# GD32L23x register map
File version: 1.0
CPU: CM23 r0p0, little endian, MPU, FPU, 4 interrupt priority bits
Registers are 32-bit, read-write, reset 0x0 unless marked. A register's access mark holds for its fields unless they carry their own. Offsets are from the block's base; [hi:lo] are bit positions; {n}, {i} and the like mark numbered series.

## SLCD — Segment LCD controller
Base 0x40002400
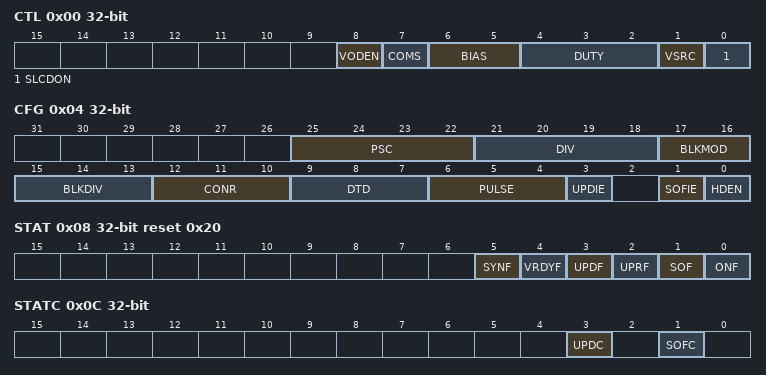
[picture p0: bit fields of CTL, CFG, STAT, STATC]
0x00 CTL — Control register
  [8] VODEN — Voltage output driver enable
  [7] COMS — Common/segment padselect
  [6:5] BIAS — Bias select
  [4:2] DUTY — Duty select
  [1] VSRC — SLCD voltage source
  [0] SLCDON — SLCD controller start
0x04 CFG — SLCD configuration register
  [25:22] PSC — SLCD clock prescaler
  [21:18] DIV — SLCD clock divider
  [17:16] BLKMOD — Blink mode
  [15:13] BLKDIV — Blink frequency divider
  [12:10] CONR — Contrast ratio
  [9:7] DTD — Dead time duration
  [6:4] PULSE — Pulse on duration
  [3] UPDIE — SLCD update done interrupt enable
  [1] SOFIE — Start of frame interrupt enable
  [0] HDEN — High drive enable
0x08 STAT access per field reset 0x20 — SLCD status flag register
  [5] SYNF ro — SLCD_CFG register synchronization flag
  [4] VRDYF ro — SLCD voltage ready flag
  [3] UPDF ro — Update SLCD data done flag
  [2] UPRF rw — Update SLCD data request flag
  [1] SOF ro — Start of frame flag
  [0] ONF ro — SLCD controller on flag
0x0C STATC — SLCD status flag clear register
  [3] UPDC — SLCD data update done clear bit
  [1] SOFC — Start of frame flag clear
{0x14+8i} DATA{i} (i=0..7) — SLCD display data register
  [31:0] SEG_DATA{i} — Each bit corresponds to one segment to display

## VREF
Base 0x40010030
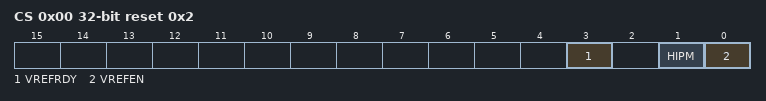
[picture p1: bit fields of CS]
0x00 CS access per field reset 0x2 — Control and status register
  [3] VREFRDY ro — VREF ready
  [1] HIPM rw — High impedance mode
  [0] VREFEN rw — VREF enable
0x04 CALIB — Calibration register
  [5:0] VREFCAL — VREF calibration

## USBD — Universal serial bus full-speed device interface
Base 0x40005C00
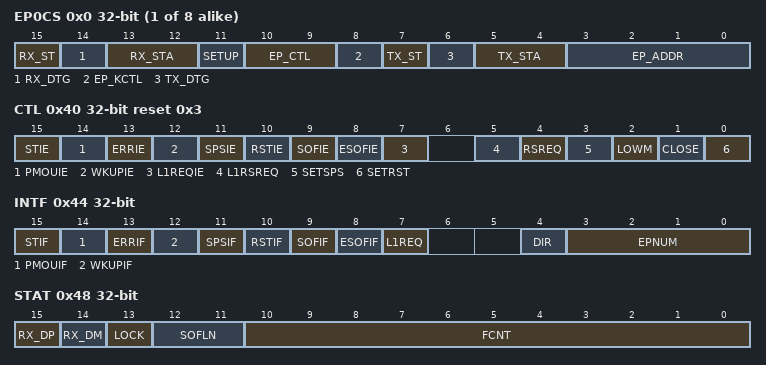
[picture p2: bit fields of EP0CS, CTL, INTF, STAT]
{0x0+4i} EP{i}CS access per field (i=0..7) — endpoint {i} register
  [15] RX_ST rw — Reception Successful Transferred
  [14] RX_DTG rw — Reception Data PID Toggle
  [13:12] RX_STA rw — Reception status bits
  [11] SETUP ro — Setup transaction completed
  [10:9] EP_CTL rw — Endpoint type control
  [8] EP_KCTL rw — Endpoint kind control
  [7] TX_ST rw — Transmission Successful Transfer
  [6] TX_DTG rw — Transmission Data PID Toggle
  [5:4] TX_STA rw — Status bits, for transmission transfers
  [3:0] EP_ADDR rw — Endpoint address
0x40 CTL reset 0x3 — control register
  [15] STIE — Successful transfer interrupt enable
  [14] PMOUIE — Packet memory overrun / underrun interrupt enable
  [13] ERRIE — Error interrupt mask
  [12] WKUPIE — Wakeup interrupt mask
  [11] SPSIE — Suspend state interrupt enable
  [10] RSTIE — USB reset interrupt enable
  [9] SOFIE — Start of frame interrupt enable
  [8] ESOFIE — Expected start of frame interrupt enable
  [7] L1REQIE — LPM L1 state request interrupt enable
  [5] L1RSREQ — LPM L1 resume request
  [4] RSREQ — Send resume request
  [3] SETSPS — Set suspend state
  [2] LOWM — Low-power mode
  [1] CLOSE — USB close
  [0] SETRST — USB Reset
0x44 INTF access per field — interrupt flag register
  [15] STIF ro — Successful transfer interrupt flag
  [14] PMOUIF rw — Packet memory overrun / underrun interrupt flag
  [13] ERRIF rw — Error interrupt flag
  [12] WKUPIF rw — Wakeup interrupt flag
  [11] SPSIF rw — Suspend state interrupt flag
  [10] RSTIF rw — USB reset interrupt flag
  [9] SOFIF rw — Start of frame interrupt flag
  [8] ESOFIF rw — Expected start of frame interrupt flag
  [7] L1REQ rw — LPM L1 transaction is successfully received and acknowledged
  [4] DIR ro — Direction of transaction
  [3:0] EPNUM ro — Endpoint Number
0x48 STAT ro — Status register
  [15] RX_DP — Receive data + line status
  [14] RX_DM — Receive data - line status
  [13] LOCK — Locked the USB
  [12:11] SOFLN — SOF lost number
  [10:0] FCNT — Frame number counter
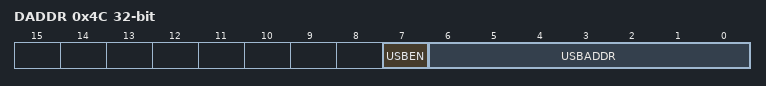
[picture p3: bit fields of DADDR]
0x4C DADDR — device address register
  [7] USBEN — USB device enable
  [6:0] USBADDR — USB device address
0x50 BADDR — Buffer address register
  [15:3] BAR — Buffer address
